AUTOSAR XML (schema 4-2-2)
package /STELLANTIS/EPT/ASWCs
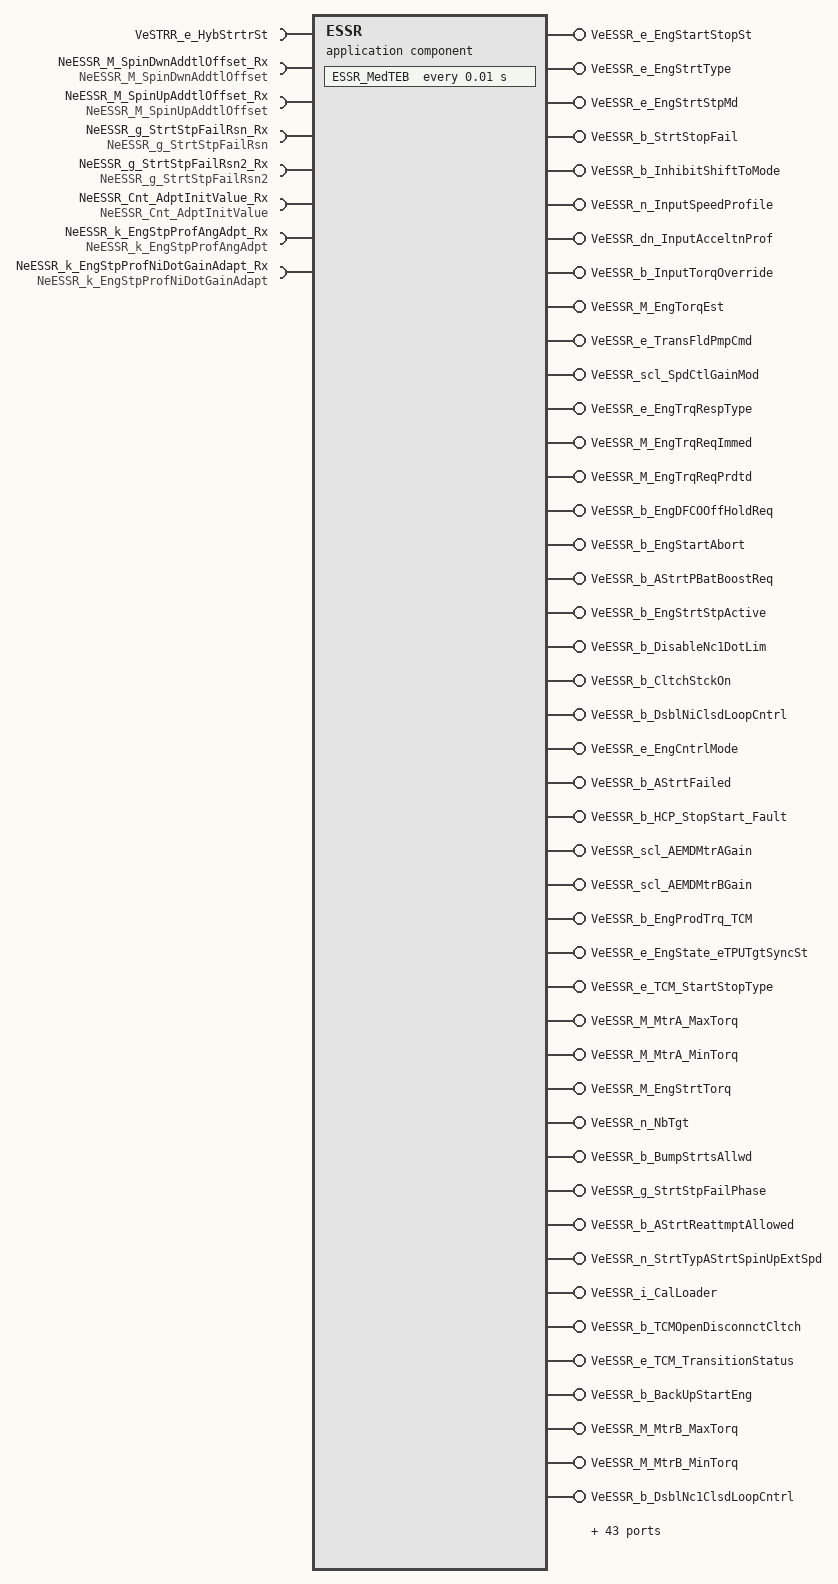
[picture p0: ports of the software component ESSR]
  application sw component type ESSR
    require port VeSTRR_e_HybStrtrSt: variation-point={short-label=vpVeSTRR_e_HybStrtrSt, sw-syscond=1}, nonqueued-receiver-com-spec{data-element=Value, init-value=CeSTRR_e_KeyOffSt}, required-interface=VeSTRR_e_HybStrtrSt
    80 x provide port:
      VeESSR_e_EngStartStopSt: variation-point={short-label=vpVeESSR_e_EngStartStopSt, sw-syscond=1}, nonqueued-sender-com-spec{data-element=Value, init-value=CeESSR_e_EngOff}, provided-interface=VeESSR_e_EngStartStopSt
      VeESSR_e_EngStrtType: variation-point={short-label=vpVeESSR_e_EngStrtType, sw-syscond=1}, nonqueued-sender-com-spec{data-element=Value, init-value=CeESSR_e_NoStrt}, provided-interface=VeESSR_e_EngStrtType
      VeESSR_e_EngStrtStpMd: variation-point={short-label=vpVeESSR_e_EngStrtStpMd, sw-syscond=1}, nonqueued-sender-com-spec{data-element=Value, init-value=CeESSR_e_Stop}, provided-interface=VeESSR_e_EngStrtStpMd
      VeESSR_b_StrtStopFail: variation-point={short-label=vpVeESSR_b_StrtStopFail, sw-syscond=1}, nonqueued-sender-com-spec{data-element=Value, init-value=0}, provided-interface=VeESSR_b_StrtStopFail
      VeESSR_b_InhibitShiftToMode: variation-point={short-label=vpVeESSR_b_InhibitShiftToMode, sw-syscond=1}, nonqueued-sender-com-spec{data-element=Value, init-value=0}, provided-interface=VeESSR_b_InhibitShiftToMode
      VeESSR_n_InputSpeedProfile: variation-point={short-label=vpVeESSR_n_InputSpeedProfile, sw-syscond=1}, nonqueued-sender-com-spec{data-element=Value, init-value=0}, provided-interface=VeESSR_n_InputSpeedProfile
      VeESSR_dn_InputAcceltnProf: variation-point={short-label=vpVeESSR_dn_InputAcceltnProf, sw-syscond=1}, nonqueued-sender-com-spec{data-element=Value, init-value=0}, provided-interface=VeESSR_dn_InputAcceltnProf
      VeESSR_b_InputTorqOverride: variation-point={short-label=vpVeESSR_b_InputTorqOverride, sw-syscond=1}, nonqueued-sender-com-spec{data-element=Value, init-value=0}, provided-interface=VeESSR_b_InputTorqOverride
      VeESSR_M_EngTorqEst: variation-point={short-label=vpVeESSR_M_EngTorqEst, sw-syscond=1}, nonqueued-sender-com-spec{data-element=Value, init-value=0}, provided-interface=VeESSR_M_EngTorqEst
      VeESSR_e_TransFldPmpCmd: variation-point={short-label=vpVeESSR_e_TransFldPmpCmd, sw-syscond=1}, nonqueued-sender-com-spec{data-element=Value, init-value=CeESSR_e_Normal}, provided-interface=VeESSR_e_TransFldPmpCmd
      VeESSR_scl_SpdCtlGainMod: variation-point={short-label=vpVeESSR_scl_SpdCtlGainMod, sw-syscond=1}, nonqueued-sender-com-spec{data-element=Value, init-value=0}, provided-interface=VeESSR_scl_SpdCtlGainMod
      VeESSR_e_EngTrqRespType: variation-point={short-label=vpVeESSR_e_EngTrqRespType, sw-syscond=1}, nonqueued-sender-com-spec{data-element=Value, init-value=CePTAR_e_Inactive}, provided-interface=VeESSR_e_EngTrqRespType
      VeESSR_M_EngTrqReqImmed: variation-point={short-label=vpVeESSR_M_EngTrqReqImmed, sw-syscond=1}, nonqueued-sender-com-spec{data-element=Value, init-value=0}, provided-interface=VeESSR_M_EngTrqReqImmed
      VeESSR_M_EngTrqReqPrdtd: variation-point={short-label=vpVeESSR_M_EngTrqReqPrdtd, sw-syscond=1}, nonqueued-sender-com-spec{data-element=Value, init-value=0}, provided-interface=VeESSR_M_EngTrqReqPrdtd
      VeESSR_b_EngDFCOOffHoldReq: variation-point={short-label=vpVeESSR_b_EngDFCOOffHoldReq, sw-syscond=1}, nonqueued-sender-com-spec{data-element=Value, init-value=0}, provided-interface=VeESSR_b_EngDFCOOffHoldReq
      VeESSR_b_EngStartAbort: variation-point={short-label=vpVeESSR_b_EngStartAbort, sw-syscond=1}, nonqueued-sender-com-spec{data-element=Value, init-value=0}, provided-interface=VeESSR_b_EngStartAbort
      VeESSR_b_AStrtPBatBoostReq: variation-point={short-label=vpVeESSR_b_AStrtPBatBoostReq, sw-syscond=1}, nonqueued-sender-com-spec{data-element=Value, init-value=0}, provided-interface=VeESSR_b_AStrtPBatBoostReq
      VeESSR_b_EngStrtStpActive: variation-point={short-label=vpVeESSR_b_EngStrtStpActive, sw-syscond=1}, nonqueued-sender-com-spec{data-element=Value, init-value=0}, provided-interface=VeESSR_b_EngStrtStpActive
      VeESSR_b_DisableNc1DotLim: variation-point={short-label=vpVeESSR_b_DisableNc1DotLim, sw-syscond=1}, nonqueued-sender-com-spec{data-element=Value, init-value=0}, provided-interface=VeESSR_b_DisableNc1DotLim
      VeESSR_b_CltchStckOn: variation-point={short-label=vpVeESSR_b_CltchStckOn, sw-syscond=1}, nonqueued-sender-com-spec{data-element=Value, init-value=0}, provided-interface=VeESSR_b_CltchStckOn
      VeESSR_b_DsblNiClsdLoopCntrl: variation-point={short-label=vpVeESSR_b_DsblNiClsdLoopCntrl, sw-syscond=1}, nonqueued-sender-com-spec{data-element=Value, init-value=0}, provided-interface=VeESSR_b_DsblNiClsdLoopCntrl
      VeESSR_e_EngCntrlMode: variation-point={short-label=vpVeESSR_e_EngCntrlMode, sw-syscond=1}, nonqueued-sender-com-spec{data-element=Value, init-value=CeTRAR_e_TorqueMode}, provided-interface=VeESSR_e_EngCntrlMode
      VeESSR_b_AStrtFailed: variation-point={short-label=vpVeESSR_b_AStrtFailed, sw-syscond=1}, nonqueued-sender-com-spec{data-element=Value, init-value=0}, provided-interface=VeESSR_b_AStrtFailed
      VeESSR_b_HCP_StopStart_Fault: variation-point={short-label=vpVeESSR_b_HCP_StopStart_Fault, sw-syscond=1}, nonqueued-sender-com-spec{data-element=Value, init-value=0}, provided-interface=VeESSR_b_HCP_StopStart_Fault
      VeESSR_scl_AEMDMtrAGain: variation-point={short-label=vpVeESSR_scl_AEMDMtrAGain, sw-syscond=1}, nonqueued-sender-com-spec{data-element=Value, init-value=0}, provided-interface=VeESSR_scl_AEMDMtrAGain
      VeESSR_scl_AEMDMtrBGain: variation-point={short-label=vpVeESSR_scl_AEMDMtrBGain, sw-syscond=1}, nonqueued-sender-com-spec{data-element=Value, init-value=0}, provided-interface=VeESSR_scl_AEMDMtrBGain
      VeESSR_b_EngProdTrq_TCM: variation-point={short-label=vpVeESSR_b_EngProdTrq_TCM, sw-syscond=1}, nonqueued-sender-com-spec{data-element=Value, init-value=0}, provided-interface=VeESSR_b_EngProdTrq_TCM
      VeESSR_e_EngState_eTPUTgtSyncSt: variation-point={short-label=vpVeESSR_e_EngState_eTPUTgtSyncSt, sw-syscond=1}, nonqueued-sender-com-spec{data-element=Value, init-value=CeESSR_e_Stopped}, provided-interface=VeESSR_e_EngState_eTPUTgtSyncSt
      VeESSR_e_TCM_StartStopType: variation-point={short-label=vpVeESSR_e_TCM_StartStopType, sw-syscond=1}, nonqueued-sender-com-spec{data-element=Value, init-value=CeESSR_e_NoAction}, provided-interface=VeESSR_e_TCM_StartStopType
      VeESSR_M_MtrA_MaxTorq: variation-point={short-label=vpVeESSR_M_MtrA_MaxTorq, sw-syscond=1}, nonqueued-sender-com-spec{data-element=Value, init-value=0}, provided-interface=VeESSR_M_MtrA_MaxTorq
      VeESSR_M_MtrA_MinTorq: variation-point={short-label=vpVeESSR_M_MtrA_MinTorq, sw-syscond=1}, nonqueued-sender-com-spec{data-element=Value, init-value=0}, provided-interface=VeESSR_M_MtrA_MinTorq
      VeESSR_M_EngStrtTorq: variation-point={short-label=vpVeESSR_M_EngStrtTorq, sw-syscond=1}, nonqueued-sender-com-spec{data-element=Value, init-value=0}, provided-interface=VeESSR_M_EngStrtTorq
      VeESSR_n_NbTgt: variation-point={short-label=vpVeESSR_n_NbTgt, sw-syscond=1}, nonqueued-sender-com-spec{data-element=Value, init-value=0}, provided-interface=VeESSR_n_NbTgt
      VeESSR_b_BumpStrtsAllwd: variation-point={short-label=vpVeESSR_b_BumpStrtsAllwd, sw-syscond=1}, nonqueued-sender-com-spec{data-element=Value, init-value=0}, provided-interface=VeESSR_b_BumpStrtsAllwd
      VeESSR_g_StrtStpFailPhase: variation-point={short-label=vpVeESSR_g_StrtStpFailPhase, sw-syscond=1}, nonqueued-sender-com-spec{data-element=Value, init-value=0}, provided-interface=VeESSR_g_StrtStpFailPhase
      VeESSR_b_AStrtReattmptAllowed: variation-point={short-label=vpVeESSR_b_AStrtReattmptAllowed, sw-syscond=1}, nonqueued-sender-com-spec{data-element=Value, init-value=0}, provided-interface=VeESSR_b_AStrtReattmptAllowed
      VeESSR_n_StrtTypAStrtSpinUpExtSpd: variation-point={short-label=vpVeESSR_n_StrtTypAStrtSpinUpExtSpd, sw-syscond=1}, nonqueued-sender-com-spec{data-element=Value, init-value=0}, provided-interface=VeESSR_n_StrtTypAStrtSpinUpExtSpd
      VeESSR_i_CalLoader: variation-point={short-label=vpVeESSR_i_CalLoader, sw-syscond=1}, nonqueued-sender-com-spec{data-element=Value, init-value=0}, provided-interface=VeESSR_i_CalLoader
      VeESSR_b_TCMOpenDisconnctCltch: variation-point={short-label=vpVeESSR_b_TCMOpenDisconnctCltch, sw-syscond=1}, nonqueued-sender-com-spec{data-element=Value, init-value=0}, provided-interface=VeESSR_b_TCMOpenDisconnctCltch
      VeESSR_e_TCM_TransitionStatus: variation-point={short-label=vpVeESSR_e_TCM_TransitionStatus, sw-syscond=1}, nonqueued-sender-com-spec{data-element=Value, init-value=CeESSR_e_Trans_Stat_Off}, provided-interface=VeESSR_e_TCM_TransitionStatus
      VeESSR_b_BackUpStartEng: variation-point={short-label=vpVeESSR_b_BackUpStartEng, sw-syscond=1}, nonqueued-sender-com-spec{data-element=Value, init-value=0}, provided-interface=VeESSR_b_BackUpStartEng
      VeESSR_M_MtrB_MaxTorq: variation-point={short-label=vpVeESSR_M_MtrB_MaxTorq, sw-syscond=1}, nonqueued-sender-com-spec{data-element=Value, init-value=0}, provided-interface=VeESSR_M_MtrB_MaxTorq
      VeESSR_M_MtrB_MinTorq: variation-point={short-label=vpVeESSR_M_MtrB_MinTorq, sw-syscond=1}, nonqueued-sender-com-spec{data-element=Value, init-value=0}, provided-interface=VeESSR_M_MtrB_MinTorq
      VeESSR_b_DsblNc1ClsdLoopCntrl: variation-point={short-label=vpVeESSR_b_DsblNc1ClsdLoopCntrl, sw-syscond=1}, nonqueued-sender-com-spec{data-element=Value, init-value=0}, provided-interface=VeESSR_b_DsblNc1ClsdLoopCntrl
      VeESSR_M_Clch5_TorqCmd: variation-point={short-label=vpVeESSR_M_Clch5_TorqCmd, sw-syscond=1}, nonqueued-sender-com-spec{data-element=Value, init-value=0}, provided-interface=VeESSR_M_Clch5_TorqCmd
      VeESSR_M_MtrC_MaxTorq: variation-point={short-label=vpVeESSR_M_MtrC_MaxTorq, sw-syscond=1}, nonqueued-sender-com-spec{data-element=Value, init-value=0}, provided-interface=VeESSR_M_MtrC_MaxTorq
      VeESSR_M_MtrC_MinTorq: variation-point={short-label=vpVeESSR_M_MtrC_MinTorq, sw-syscond=1}, nonqueued-sender-com-spec{data-element=Value, init-value=0}, provided-interface=VeESSR_M_MtrC_MinTorq
      VeESSR_b_NbTgtReq: variation-point={short-label=vpVeESSR_b_NbTgtReq, sw-syscond=1}, nonqueued-sender-com-spec{data-element=Value, init-value=0}, provided-interface=VeESSR_b_NbTgtReq
      VeESSR_b_EngStallReattmpAllwd: variation-point={short-label=vpVeESSR_b_EngStallReattmpAllwd, sw-syscond=1}, nonqueued-sender-com-spec{data-element=Value, init-value=0}, provided-interface=VeESSR_b_EngStallReattmpAllwd
      VeESSR_M_MtrAPulseCancelTrq: variation-point={short-label=vpVeESSR_M_MtrAPulseCancelTrq, sw-syscond=1}, nonqueued-sender-com-spec{data-element=Value, init-value=0}, provided-interface=VeESSR_M_MtrAPulseCancelTrq
      VeESSR_M_MtrBPulseCancelTrq: variation-point={short-label=vpVeESSR_M_MtrBPulseCancelTrq, sw-syscond=1}, nonqueued-sender-com-spec{data-element=Value, init-value=0}, provided-interface=VeESSR_M_MtrBPulseCancelTrq
      VeESSR_b_IUMPR_P1C64Fail: variation-point={short-label=vpVeESSR_b_IUMPR_P1C64Fail, sw-syscond=1}, nonqueued-sender-com-spec{data-element=Value, init-value=0}, provided-interface=VeESSR_b_IUMPR_P1C64Fail
      VeESSR_b_IUMPR_P1C65Fail: variation-point={short-label=vpVeESSR_b_IUMPR_P1C65Fail, sw-syscond=1}, nonqueued-sender-com-spec{data-element=Value, init-value=0}, provided-interface=VeESSR_b_IUMPR_P1C65Fail
      VeESSR_b_IUMPR_P1C68Fail: variation-point={short-label=vpVeESSR_b_IUMPR_P1C68Fail, sw-syscond=1}, nonqueued-sender-com-spec{data-element=Value, init-value=0}, provided-interface=VeESSR_b_IUMPR_P1C68Fail
      VeESSR_e_HybEngSysActv: variation-point={short-label=vpVeESSR_e_HybEngSysActv, sw-syscond=1}, nonqueued-sender-com-spec{data-element=Value, init-value=CeESSR_e_HybEngDisabled}, provided-interface=VeESSR_e_HybEngSysActv
      VeESSR_b_BSGStrtFailed: variation-point={short-label=vpVeESSR_b_BSGStrtFailed, sw-syscond=1}, nonqueued-sender-com-spec{data-element=Value, init-value=0}, provided-interface=VeESSR_b_BSGStrtFailed
      VeESSR_b_BkupStrtsAllwd: variation-point={short-label=vpVeESSR_b_BkupStrtsAllwd, sw-syscond=1}, nonqueued-sender-com-spec{data-element=Value, init-value=0}, provided-interface=VeESSR_b_BkupStrtsAllwd
      VeESSR_Cnt_CSSpinupAttmptCntr: variation-point={short-label=vpVeESSR_Cnt_CSSpinupAttmptCntr, sw-syscond=1}, nonqueued-sender-com-spec{data-element=Value, init-value=0}, provided-interface=VeESSR_Cnt_CSSpinupAttmptCntr
      VeESSR_Cnt_EMSpinupAttmptCntr: variation-point={short-label=vpVeESSR_Cnt_EMSpinupAttmptCntr, sw-syscond=1}, nonqueued-sender-com-spec{data-element=Value, init-value=0}, provided-interface=VeESSR_Cnt_EMSpinupAttmptCntr
      VeESSR_e_EngStrtProfType: variation-point={short-label=vpVeESSR_e_EngStrtProfType, sw-syscond=1}, nonqueued-sender-com-spec{data-element=Value, init-value=CeESSR_e_NoStart}, provided-interface=VeESSR_e_EngStrtProfType
      VeESSR_n_OptInputSpd: variation-point={short-label=vpVeESSR_n_OptInputSpd, sw-syscond=1}, nonqueued-sender-com-spec{data-element=Value, init-value=0}, provided-interface=VeESSR_n_OptInputSpd
      VeESSR_n_TgtIdleSpd: variation-point={short-label=vpVeESSR_n_TgtIdleSpd, sw-syscond=1}, nonqueued-sender-com-spec{data-element=Value, init-value=0}, provided-interface=VeESSR_n_TgtIdleSpd
      VeESSR_b_OptimdEngOnOffCmd: variation-point={short-label=vpVeESSR_b_OptimdEngOnOffCmd, sw-syscond=1}, nonqueued-sender-com-spec{data-element=Value, init-value=0}, provided-interface=VeESSR_b_OptimdEngOnOffCmd
      VeESSR_b_HCPFuelDisable: variation-point={short-label=vpVeESSR_b_HCPFuelDisable, sw-syscond=1}, nonqueued-sender-com-spec{data-element=Value, init-value=0}, provided-interface=VeESSR_b_HCPFuelDisable
      VeESSR_b_Hyb_ProducingTorque: variation-point={short-label=vpVeESSR_b_Hyb_ProducingTorque, sw-syscond=1}, nonqueued-sender-com-spec{data-element=Value, init-value=0}, provided-interface=VeESSR_b_Hyb_ProducingTorque
      VeESSR_e_OptimdEngStrtStpType: variation-point={short-label=vpVeESSR_e_OptimdEngStrtStpType, sw-syscond=1}, nonqueued-sender-com-spec{data-element=Value, init-value=CeESSR_e_NoStrt}, provided-interface=VeESSR_e_OptimdEngStrtStpType
      VeESSR_e_OptimdStrtReqdActr: variation-point={short-label=vpVeESSR_e_OptimdStrtReqdActr, sw-syscond=1}, nonqueued-sender-com-spec{data-element=Value, init-value=CeESSR_e_NoActTyp}, provided-interface=VeESSR_e_OptimdStrtReqdActr
      VeESSR_b_EngOffAllwdECM: variation-point={short-label=vpVeESSR_b_EngOffAllwdECM, sw-syscond=1}, nonqueued-sender-com-spec{data-element=Value, init-value=0}, provided-interface=VeESSR_b_EngOffAllwdECM
      VeESSR_r_MaxSparkAuthority: variation-point={short-label=vpVeESSR_r_MaxSparkAuthority, sw-syscond=1}, nonqueued-sender-com-spec{data-element=Value, init-value=0}, provided-interface=VeESSR_r_MaxSparkAuthority
      VeESSR_M_EngineLosses: variation-point={short-label=vpVeESSR_M_EngineLosses, sw-syscond=1}, nonqueued-sender-com-spec{data-element=Value, init-value=0}, provided-interface=VeESSR_M_EngineLosses
      VeESSR_b_P1C64_Failed: variation-point={short-label=vpVeESSR_b_P1C64_Failed, sw-syscond=1}, nonqueued-sender-com-spec{data-element=Value, init-value=0}, provided-interface=VeESSR_b_P1C64_Failed
      VeESSR_b_P1C65_Failed: variation-point={short-label=vpVeESSR_b_P1C65_Failed, sw-syscond=1}, nonqueued-sender-com-spec{data-element=Value, init-value=0}, provided-interface=VeESSR_b_P1C65_Failed
      VeESSR_b_P1C68_Failed: variation-point={short-label=vpVeESSR_b_P1C68_Failed, sw-syscond=1}, nonqueued-sender-com-spec{data-element=Value, init-value=0}, provided-interface=VeESSR_b_P1C68_Failed
      VeESSR_b_P1C64_Passed: variation-point={short-label=vpVeESSR_b_P1C64_Passed, sw-syscond=1}, nonqueued-sender-com-spec{data-element=Value, init-value=0}, provided-interface=VeESSR_b_P1C64_Passed
      VeESSR_b_P1C65_Passed: variation-point={short-label=vpVeESSR_b_P1C65_Passed, sw-syscond=1}, nonqueued-sender-com-spec{data-element=Value, init-value=0}, provided-interface=VeESSR_b_P1C65_Passed
      VeESSR_b_P1C68_Passed: variation-point={short-label=vpVeESSR_b_P1C68_Passed, sw-syscond=1}, nonqueued-sender-com-spec{data-element=Value, init-value=0}, provided-interface=VeESSR_b_P1C68_Passed
      VeESSR_n_NiPred: variation-point={short-label=vpVeESSR_n_NiPred, sw-syscond=1}, nonqueued-sender-com-spec{data-element=Value, init-value=0}, provided-interface=VeESSR_n_NiPred
      VeESSR_b_DisableMtrA: variation-point={short-label=vpVeESSR_b_DisableMtrA, sw-syscond=1}, nonqueued-sender-com-spec{data-element=Value, init-value=0}, provided-interface=VeESSR_b_DisableMtrA
      VeESSR_M_BCTiMargin: variation-point={short-label=vpVeESSR_M_BCTiMargin, sw-syscond=1}, nonqueued-sender-com-spec{data-element=Value, init-value=0}, provided-interface=VeESSR_M_BCTiMargin
      VeESSR_g_StrtStpFailRsn: variation-point={short-label=vpVeESSR_g_StrtStpFailRsn, sw-syscond=1}, nonqueued-sender-com-spec{data-element=Value, init-value=0}, provided-interface=VeESSR_g_StrtStpFailRsn
    7 x require port:
      NeESSR_M_SpinDwnAddtlOffset_Rx: nv-require-com-spec{init-value=0, variable=NeESSR_M_SpinDwnAddtlOffset}, required-interface=NeESSR_M_SpinDwnAddtlOffset
      NeESSR_M_SpinUpAddtlOffset_Rx: nv-require-com-spec{init-value=0, variable=NeESSR_M_SpinUpAddtlOffset}, required-interface=NeESSR_M_SpinUpAddtlOffset
      NeESSR_g_StrtStpFailRsn_Rx: nv-require-com-spec{init-value=0, variable=NeESSR_g_StrtStpFailRsn}, required-interface=NeESSR_g_StrtStpFailRsn
      NeESSR_g_StrtStpFailRsn2_Rx: nv-require-com-spec{init-value=0, variable=NeESSR_g_StrtStpFailRsn2}, required-interface=NeESSR_g_StrtStpFailRsn2
      NeESSR_Cnt_AdptInitValue_Rx: nv-require-com-spec{init-value=0, variable=NeESSR_Cnt_AdptInitValue}, required-interface=NeESSR_Cnt_AdptInitValue
      NeESSR_k_EngStpProfAngAdpt_Rx: nv-require-com-spec{init-value=0, variable=NeESSR_k_EngStpProfAngAdpt}, required-interface=NeESSR_k_EngStpProfAngAdpt
      NeESSR_k_EngStpProfNiDotGainAdapt_Rx: nv-require-com-spec{init-value=0, variable=NeESSR_k_EngStpProfNiDotGainAdapt}, required-interface=NeESSR_k_EngStpProfNiDotGainAdapt
    7 x provide port:
      NeESSR_M_SpinDwnAddtlOffset: nv-provide-com-spec{ram-block-init-value=0, variable=NeESSR_M_SpinDwnAddtlOffset}, provided-interface=NeESSR_M_SpinDwnAddtlOffset
      NeESSR_M_SpinUpAddtlOffset: nv-provide-com-spec{ram-block-init-value=0, variable=NeESSR_M_SpinUpAddtlOffset}, provided-interface=NeESSR_M_SpinUpAddtlOffset
      NeESSR_g_StrtStpFailRsn: nv-provide-com-spec{ram-block-init-value=0, variable=NeESSR_g_StrtStpFailRsn}, provided-interface=NeESSR_g_StrtStpFailRsn
      NeESSR_g_StrtStpFailRsn2: nv-provide-com-spec{ram-block-init-value=0, variable=NeESSR_g_StrtStpFailRsn2}, provided-interface=NeESSR_g_StrtStpFailRsn2
      NeESSR_Cnt_AdptInitValue: nv-provide-com-spec{ram-block-init-value=0, variable=NeESSR_Cnt_AdptInitValue}, provided-interface=NeESSR_Cnt_AdptInitValue
      NeESSR_k_EngStpProfAngAdpt: nv-provide-com-spec{ram-block-init-value=0, variable=NeESSR_k_EngStpProfAngAdpt}, provided-interface=NeESSR_k_EngStpProfAngAdpt
      NeESSR_k_EngStpProfNiDotGainAdapt: nv-provide-com-spec{ram-block-init-value=0, variable=NeESSR_k_EngStpProfNiDotGainAdapt}, provided-interface=NeESSR_k_EngStpProfNiDotGainAdapt
    behavior IB_ESSR: data-type-mapping=msADTtoIDTMapping, handle-termination-and-restart=NO-SUPPORT, included-data-type-set=data-type=[TeESSR_e_IdleCtrlrSelect, TeESSR_e_STMTrigger, TeESSR_e_StrtStpFailDTC]
      timing event Event_MedTEB: start-on-event=ESSR_MedTEB, period=0.01
      init event Event_ESSR_ac_Init: start-on-event=ESSR_ac_Init
      init event Event_PwrOn: start-on-event=ESSR_PwrOn
      init event Event_PwrOff: start-on-event=ESSR_PwrOff
      4 x runnable:
        ESSR_ac_Init
          data-send-points:
            13 x access:
              OUT_VeESSR_e_EngStartStopSt_Value: accessed-variable=VeESSR_e_EngStartStopSt.Value, variation-point={short-label=vpOUT_VeESSR_e_EngStartStopSt_Value, sw-syscond=1}
              OUT_VeESSR_e_EngStrtType_Value: accessed-variable=VeESSR_e_EngStrtType.Value, variation-point={short-label=vpOUT_VeESSR_e_EngStrtType_Value, sw-syscond=1}
              OUT_VeESSR_e_EngStrtStpMd_Value: accessed-variable=VeESSR_e_EngStrtStpMd.Value, variation-point={short-label=vpOUT_VeESSR_e_EngStrtStpMd_Value, sw-syscond=1}
              OUT_VeESSR_e_TransFldPmpCmd_Value: accessed-variable=VeESSR_e_TransFldPmpCmd.Value, variation-point={short-label=vpOUT_VeESSR_e_TransFldPmpCmd_Value, sw-syscond=1}
              OUT_VeESSR_e_EngTrqRespType_Value: accessed-variable=VeESSR_e_EngTrqRespType.Value, variation-point={short-label=vpOUT_VeESSR_e_EngTrqRespType_Value, sw-syscond=1}
              OUT_VeESSR_e_EngCntrlMode_Value: accessed-variable=VeESSR_e_EngCntrlMode.Value, variation-point={short-label=vpOUT_VeESSR_e_EngCntrlMode_Value, sw-syscond=1}
              OUT_VeESSR_e_EngState_eTPUTgtSyncSt_Value: accessed-variable=VeESSR_e_EngState_eTPUTgtSyncSt.Value, variation-point={short-label=vpOUT_VeESSR_e_EngState_eTPUTgtSyncSt_Value, sw-syscond=1}
              OUT_VeESSR_e_TCM_StartStopType_Value: accessed-variable=VeESSR_e_TCM_StartStopType.Value, variation-point={short-label=vpOUT_VeESSR_e_TCM_StartStopType_Value, sw-syscond=1}
              OUT_VeESSR_e_TCM_TransitionStatus_Value: accessed-variable=VeESSR_e_TCM_TransitionStatus.Value, variation-point={short-label=vpOUT_VeESSR_e_TCM_TransitionStatus_Value, sw-syscond=1}
              OUT_VeESSR_e_HybEngSysActv_Value: accessed-variable=VeESSR_e_HybEngSysActv.Value, variation-point={short-label=vpOUT_VeESSR_e_HybEngSysActv_Value, sw-syscond=1}
              OUT_VeESSR_e_EngStrtProfType_Value: accessed-variable=VeESSR_e_EngStrtProfType.Value, variation-point={short-label=vpOUT_VeESSR_e_EngStrtProfType_Value, sw-syscond=1}
              OUT_VeESSR_e_OptimdEngStrtStpType_Value: accessed-variable=VeESSR_e_OptimdEngStrtStpType.Value, variation-point={short-label=vpOUT_VeESSR_e_OptimdEngStrtStpType_Value, sw-syscond=1}
              OUT_VeESSR_e_OptimdStrtReqdActr_Value: accessed-variable=VeESSR_e_OptimdStrtReqdActr.Value, variation-point={short-label=vpOUT_VeESSR_e_OptimdStrtReqdActr_Value, sw-syscond=1}
        ESSR_PwrOn
          data-receive-point-by-arguments:
            7 x access:
              IN_NeESSR_Cnt_AdptInitValue_Rx_NeESSR_Cnt_AdptInitValue: accessed-variable=NeESSR_Cnt_AdptInitValue_Rx.NeESSR_Cnt_AdptInitValue
              IN_NeESSR_M_SpinDwnAddtlOffset_Rx_NeESSR_M_SpinDwnAddtlOffset: accessed-variable=NeESSR_M_SpinDwnAddtlOffset_Rx.NeESSR_M_SpinDwnAddtlOffset
              IN_NeESSR_M_SpinUpAddtlOffset_Rx_NeESSR_M_SpinUpAddtlOffset: accessed-variable=NeESSR_M_SpinUpAddtlOffset_Rx.NeESSR_M_SpinUpAddtlOffset
              IN_NeESSR_g_StrtStpFailRsn2_Rx_NeESSR_g_StrtStpFailRsn2: accessed-variable=NeESSR_g_StrtStpFailRsn2_Rx.NeESSR_g_StrtStpFailRsn2
              IN_NeESSR_g_StrtStpFailRsn_Rx_NeESSR_g_StrtStpFailRsn: accessed-variable=NeESSR_g_StrtStpFailRsn_Rx.NeESSR_g_StrtStpFailRsn
              IN_NeESSR_k_EngStpProfAngAdpt_Rx_NeESSR_k_EngStpProfAngAdpt: accessed-variable=NeESSR_k_EngStpProfAngAdpt_Rx.NeESSR_k_EngStpProfAngAdpt
              IN_NeESSR_k_EngStpProfNiDotGainAdapt_Rx_NeESSR_k_EngStpProfNiDotGainAdapt: accessed-variable=NeESSR_k_EngStpProfNiDotGainAdapt_Rx.NeESSR_k_EngStpProfNiDotGainAdapt
          data-send-points:
            80 x access:
              OUT_VeESSR_e_EngStartStopSt_Value: accessed-variable=VeESSR_e_EngStartStopSt.Value, variation-point={short-label=vpOUT_VeESSR_e_EngStartStopSt_Value, sw-syscond=1}
              OUT_VeESSR_e_TransFldPmpCmd_Value: accessed-variable=VeESSR_e_TransFldPmpCmd.Value, variation-point={short-label=vpOUT_VeESSR_e_TransFldPmpCmd_Value, sw-syscond=1}
              OUT_VeESSR_scl_SpdCtlGainMod_Value: accessed-variable=VeESSR_scl_SpdCtlGainMod.Value, variation-point={short-label=vpOUT_VeESSR_scl_SpdCtlGainMod_Value, sw-syscond=1}
              OUT_VeESSR_e_EngTrqRespType_Value: accessed-variable=VeESSR_e_EngTrqRespType.Value, variation-point={short-label=vpOUT_VeESSR_e_EngTrqRespType_Value, sw-syscond=1}
              OUT_VeESSR_M_EngTrqReqImmed_Value: accessed-variable=VeESSR_M_EngTrqReqImmed.Value, variation-point={short-label=vpOUT_VeESSR_M_EngTrqReqImmed_Value, sw-syscond=1}
              OUT_VeESSR_M_EngTrqReqPrdtd_Value: accessed-variable=VeESSR_M_EngTrqReqPrdtd.Value, variation-point={short-label=vpOUT_VeESSR_M_EngTrqReqPrdtd_Value, sw-syscond=1}
              OUT_VeESSR_b_EngDFCOOffHoldReq_Value: accessed-variable=VeESSR_b_EngDFCOOffHoldReq.Value, variation-point={short-label=vpOUT_VeESSR_b_EngDFCOOffHoldReq_Value, sw-syscond=1}
              OUT_VeESSR_b_EngStartAbort_Value: accessed-variable=VeESSR_b_EngStartAbort.Value, variation-point={short-label=vpOUT_VeESSR_b_EngStartAbort_Value, sw-syscond=1}
              OUT_VeESSR_b_AStrtPBatBoostReq_Value: accessed-variable=VeESSR_b_AStrtPBatBoostReq.Value, variation-point={short-label=vpOUT_VeESSR_b_AStrtPBatBoostReq_Value, sw-syscond=1}
              OUT_VeESSR_b_EngStrtStpActive_Value: accessed-variable=VeESSR_b_EngStrtStpActive.Value, variation-point={short-label=vpOUT_VeESSR_b_EngStrtStpActive_Value, sw-syscond=1}
              OUT_VeESSR_b_DisableNc1DotLim_Value: accessed-variable=VeESSR_b_DisableNc1DotLim.Value, variation-point={short-label=vpOUT_VeESSR_b_DisableNc1DotLim_Value, sw-syscond=1}
              OUT_VeESSR_e_EngStrtType_Value: accessed-variable=VeESSR_e_EngStrtType.Value, variation-point={short-label=vpOUT_VeESSR_e_EngStrtType_Value, sw-syscond=1}
              OUT_VeESSR_b_CltchStckOn_Value: accessed-variable=VeESSR_b_CltchStckOn.Value, variation-point={short-label=vpOUT_VeESSR_b_CltchStckOn_Value, sw-syscond=1}
              OUT_VeESSR_b_DsblNiClsdLoopCntrl_Value: accessed-variable=VeESSR_b_DsblNiClsdLoopCntrl.Value, variation-point={short-label=vpOUT_VeESSR_b_DsblNiClsdLoopCntrl_Value, sw-syscond=1}
              OUT_VeESSR_e_EngCntrlMode_Value: accessed-variable=VeESSR_e_EngCntrlMode.Value, variation-point={short-label=vpOUT_VeESSR_e_EngCntrlMode_Value, sw-syscond=1}
              OUT_VeESSR_b_AStrtFailed_Value: accessed-variable=VeESSR_b_AStrtFailed.Value, variation-point={short-label=vpOUT_VeESSR_b_AStrtFailed_Value, sw-syscond=1}
              OUT_VeESSR_b_HCP_StopStart_Fault_Value: accessed-variable=VeESSR_b_HCP_StopStart_Fault.Value, variation-point={short-label=vpOUT_VeESSR_b_HCP_StopStart_Fault_Value, sw-syscond=1}
              OUT_VeESSR_scl_AEMDMtrAGain_Value: accessed-variable=VeESSR_scl_AEMDMtrAGain.Value, variation-point={short-label=vpOUT_VeESSR_scl_AEMDMtrAGain_Value, sw-syscond=1}
              OUT_VeESSR_scl_AEMDMtrBGain_Value: accessed-variable=VeESSR_scl_AEMDMtrBGain.Value, variation-point={short-label=vpOUT_VeESSR_scl_AEMDMtrBGain_Value, sw-syscond=1}
              OUT_VeESSR_b_EngProdTrq_TCM_Value: accessed-variable=VeESSR_b_EngProdTrq_TCM.Value, variation-point={short-label=vpOUT_VeESSR_b_EngProdTrq_TCM_Value, sw-syscond=1}
              OUT_VeESSR_e_EngState_eTPUTgtSyncSt_Value: accessed-variable=VeESSR_e_EngState_eTPUTgtSyncSt.Value, variation-point={short-label=vpOUT_VeESSR_e_EngState_eTPUTgtSyncSt_Value, sw-syscond=1}
              OUT_VeESSR_e_TCM_StartStopType_Value: accessed-variable=VeESSR_e_TCM_StartStopType.Value, variation-point={short-label=vpOUT_VeESSR_e_TCM_StartStopType_Value, sw-syscond=1}
              OUT_VeESSR_e_EngStrtStpMd_Value: accessed-variable=VeESSR_e_EngStrtStpMd.Value, variation-point={short-label=vpOUT_VeESSR_e_EngStrtStpMd_Value, sw-syscond=1}
              OUT_VeESSR_M_MtrA_MaxTorq_Value: accessed-variable=VeESSR_M_MtrA_MaxTorq.Value, variation-point={short-label=vpOUT_VeESSR_M_MtrA_MaxTorq_Value, sw-syscond=1}
              OUT_VeESSR_M_MtrA_MinTorq_Value: accessed-variable=VeESSR_M_MtrA_MinTorq.Value, variation-point={short-label=vpOUT_VeESSR_M_MtrA_MinTorq_Value, sw-syscond=1}
              OUT_VeESSR_M_EngStrtTorq_Value: accessed-variable=VeESSR_M_EngStrtTorq.Value, variation-point={short-label=vpOUT_VeESSR_M_EngStrtTorq_Value, sw-syscond=1}
              OUT_VeESSR_n_NbTgt_Value: accessed-variable=VeESSR_n_NbTgt.Value, variation-point={short-label=vpOUT_VeESSR_n_NbTgt_Value, sw-syscond=1}
              OUT_VeESSR_b_BumpStrtsAllwd_Value: accessed-variable=VeESSR_b_BumpStrtsAllwd.Value, variation-point={short-label=vpOUT_VeESSR_b_BumpStrtsAllwd_Value, sw-syscond=1}
              OUT_VeESSR_g_StrtStpFailPhase_Value: accessed-variable=VeESSR_g_StrtStpFailPhase.Value, variation-point={short-label=vpOUT_VeESSR_g_StrtStpFailPhase_Value, sw-syscond=1}
              OUT_VeESSR_b_AStrtReattmptAllowed_Value: accessed-variable=VeESSR_b_AStrtReattmptAllowed.Value, variation-point={short-label=vpOUT_VeESSR_b_AStrtReattmptAllowed_Value, sw-syscond=1}
              OUT_VeESSR_n_StrtTypAStrtSpinUpExtSpd_Value: accessed-variable=VeESSR_n_StrtTypAStrtSpinUpExtSpd.Value, variation-point={short-label=vpOUT_VeESSR_n_StrtTypAStrtSpinUpExtSpd_Value, sw-syscond=1}
              OUT_VeESSR_i_CalLoader_Value: accessed-variable=VeESSR_i_CalLoader.Value, variation-point={short-label=vpOUT_VeESSR_i_CalLoader_Value, sw-syscond=1}
              OUT_VeESSR_b_TCMOpenDisconnctCltch_Value: accessed-variable=VeESSR_b_TCMOpenDisconnctCltch.Value, variation-point={short-label=vpOUT_VeESSR_b_TCMOpenDisconnctCltch_Value, sw-syscond=1}
              OUT_VeESSR_b_StrtStopFail_Value: accessed-variable=VeESSR_b_StrtStopFail.Value, variation-point={short-label=vpOUT_VeESSR_b_StrtStopFail_Value, sw-syscond=1}
              OUT_VeESSR_e_TCM_TransitionStatus_Value: accessed-variable=VeESSR_e_TCM_TransitionStatus.Value, variation-point={short-label=vpOUT_VeESSR_e_TCM_TransitionStatus_Value, sw-syscond=1}
              OUT_VeESSR_b_BackUpStartEng_Value: accessed-variable=VeESSR_b_BackUpStartEng.Value, variation-point={short-label=vpOUT_VeESSR_b_BackUpStartEng_Value, sw-syscond=1}
              OUT_VeESSR_M_MtrB_MaxTorq_Value: accessed-variable=VeESSR_M_MtrB_MaxTorq.Value, variation-point={short-label=vpOUT_VeESSR_M_MtrB_MaxTorq_Value, sw-syscond=1}
              OUT_VeESSR_M_MtrB_MinTorq_Value: accessed-variable=VeESSR_M_MtrB_MinTorq.Value, variation-point={short-label=vpOUT_VeESSR_M_MtrB_MinTorq_Value, sw-syscond=1}
              OUT_VeESSR_b_DsblNc1ClsdLoopCntrl_Value: accessed-variable=VeESSR_b_DsblNc1ClsdLoopCntrl.Value, variation-point={short-label=vpOUT_VeESSR_b_DsblNc1ClsdLoopCntrl_Value, sw-syscond=1}
              OUT_VeESSR_M_Clch5_TorqCmd_Value: accessed-variable=VeESSR_M_Clch5_TorqCmd.Value, variation-point={short-label=vpOUT_VeESSR_M_Clch5_TorqCmd_Value, sw-syscond=1}
              OUT_VeESSR_M_MtrC_MaxTorq_Value: accessed-variable=VeESSR_M_MtrC_MaxTorq.Value, variation-point={short-label=vpOUT_VeESSR_M_MtrC_MaxTorq_Value, sw-syscond=1}
              OUT_VeESSR_M_MtrC_MinTorq_Value: accessed-variable=VeESSR_M_MtrC_MinTorq.Value, variation-point={short-label=vpOUT_VeESSR_M_MtrC_MinTorq_Value, sw-syscond=1}
              OUT_VeESSR_b_NbTgtReq_Value: accessed-variable=VeESSR_b_NbTgtReq.Value, variation-point={short-label=vpOUT_VeESSR_b_NbTgtReq_Value, sw-syscond=1}
              OUT_VeESSR_b_EngStallReattmpAllwd_Value: accessed-variable=VeESSR_b_EngStallReattmpAllwd.Value, variation-point={short-label=vpOUT_VeESSR_b_EngStallReattmpAllwd_Value, sw-syscond=1}
              OUT_VeESSR_b_InhibitShiftToMode_Value: accessed-variable=VeESSR_b_InhibitShiftToMode.Value, variation-point={short-label=vpOUT_VeESSR_b_InhibitShiftToMode_Value, sw-syscond=1}
              OUT_VeESSR_b_BSGStrtFailed_Value: accessed-variable=VeESSR_b_BSGStrtFailed.Value, variation-point={short-label=vpOUT_VeESSR_b_BSGStrtFailed_Value, sw-syscond=1}
              OUT_VeESSR_b_BkupStrtsAllwd_Value: accessed-variable=VeESSR_b_BkupStrtsAllwd.Value, variation-point={short-label=vpOUT_VeESSR_b_BkupStrtsAllwd_Value, sw-syscond=1}
              OUT_VeESSR_Cnt_CSSpinupAttmptCntr_Value: accessed-variable=VeESSR_Cnt_CSSpinupAttmptCntr.Value, variation-point={short-label=vpOUT_VeESSR_Cnt_CSSpinupAttmptCntr_Value, sw-syscond=1}
              OUT_VeESSR_Cnt_EMSpinupAttmptCntr_Value: accessed-variable=VeESSR_Cnt_EMSpinupAttmptCntr.Value, variation-point={short-label=vpOUT_VeESSR_Cnt_EMSpinupAttmptCntr_Value, sw-syscond=1}
              OUT_VeESSR_e_EngStrtProfType_Value: accessed-variable=VeESSR_e_EngStrtProfType.Value, variation-point={short-label=vpOUT_VeESSR_e_EngStrtProfType_Value, sw-syscond=1}
              OUT_VeESSR_n_OptInputSpd_Value: accessed-variable=VeESSR_n_OptInputSpd.Value, variation-point={short-label=vpOUT_VeESSR_n_OptInputSpd_Value, sw-syscond=1}
              OUT_VeESSR_n_TgtIdleSpd_Value: accessed-variable=VeESSR_n_TgtIdleSpd.Value, variation-point={short-label=vpOUT_VeESSR_n_TgtIdleSpd_Value, sw-syscond=1}
              OUT_VeESSR_b_OptimdEngOnOffCmd_Value: accessed-variable=VeESSR_b_OptimdEngOnOffCmd.Value, variation-point={short-label=vpOUT_VeESSR_b_OptimdEngOnOffCmd_Value, sw-syscond=1}
              OUT_VeESSR_b_HCPFuelDisable_Value: accessed-variable=VeESSR_b_HCPFuelDisable.Value, variation-point={short-label=vpOUT_VeESSR_b_HCPFuelDisable_Value, sw-syscond=1}
              OUT_VeESSR_b_Hyb_ProducingTorque_Value: accessed-variable=VeESSR_b_Hyb_ProducingTorque.Value, variation-point={short-label=vpOUT_VeESSR_b_Hyb_ProducingTorque_Value, sw-syscond=1}
              OUT_VeESSR_n_InputSpeedProfile_Value: accessed-variable=VeESSR_n_InputSpeedProfile.Value, variation-point={short-label=vpOUT_VeESSR_n_InputSpeedProfile_Value, sw-syscond=1}
              OUT_VeESSR_e_OptimdEngStrtStpType_Value: accessed-variable=VeESSR_e_OptimdEngStrtStpType.Value, variation-point={short-label=vpOUT_VeESSR_e_OptimdEngStrtStpType_Value, sw-syscond=1}
              OUT_VeESSR_e_OptimdStrtReqdActr_Value: accessed-variable=VeESSR_e_OptimdStrtReqdActr.Value, variation-point={short-label=vpOUT_VeESSR_e_OptimdStrtReqdActr_Value, sw-syscond=1}
              OUT_VeESSR_b_EngOffAllwdECM_Value: accessed-variable=VeESSR_b_EngOffAllwdECM.Value, variation-point={short-label=vpOUT_VeESSR_b_EngOffAllwdECM_Value, sw-syscond=1}
              OUT_VeESSR_M_MtrAPulseCancelTrq_Value: accessed-variable=VeESSR_M_MtrAPulseCancelTrq.Value, variation-point={short-label=vpOUT_VeESSR_M_MtrAPulseCancelTrq_Value, sw-syscond=1}
              OUT_VeESSR_M_MtrBPulseCancelTrq_Value: accessed-variable=VeESSR_M_MtrBPulseCancelTrq.Value, variation-point={short-label=vpOUT_VeESSR_M_MtrBPulseCancelTrq_Value, sw-syscond=1}
              OUT_VeESSR_b_IUMPR_P1C64Fail_Value: accessed-variable=VeESSR_b_IUMPR_P1C64Fail.Value, variation-point={short-label=vpOUT_VeESSR_b_IUMPR_P1C64Fail_Value, sw-syscond=1}
              OUT_VeESSR_b_IUMPR_P1C65Fail_Value: accessed-variable=VeESSR_b_IUMPR_P1C65Fail.Value, variation-point={short-label=vpOUT_VeESSR_b_IUMPR_P1C65Fail_Value, sw-syscond=1}
              OUT_VeESSR_b_IUMPR_P1C68Fail_Value: accessed-variable=VeESSR_b_IUMPR_P1C68Fail.Value, variation-point={short-label=vpOUT_VeESSR_b_IUMPR_P1C68Fail_Value, sw-syscond=1}
              OUT_VeESSR_r_MaxSparkAuthority_Value: accessed-variable=VeESSR_r_MaxSparkAuthority.Value, variation-point={short-label=vpOUT_VeESSR_r_MaxSparkAuthority_Value, sw-syscond=1}
              OUT_VeESSR_dn_InputAcceltnProf_Value: accessed-variable=VeESSR_dn_InputAcceltnProf.Value, variation-point={short-label=vpOUT_VeESSR_dn_InputAcceltnProf_Value, sw-syscond=1}
              OUT_VeESSR_M_EngineLosses_Value: accessed-variable=VeESSR_M_EngineLosses.Value, variation-point={short-label=vpOUT_VeESSR_M_EngineLosses_Value, sw-syscond=1}
              OUT_VeESSR_b_P1C64_Failed_Value: accessed-variable=VeESSR_b_P1C64_Failed.Value, variation-point={short-label=vpOUT_VeESSR_b_P1C64_Failed_Value, sw-syscond=1}
              OUT_VeESSR_b_P1C65_Failed_Value: accessed-variable=VeESSR_b_P1C65_Failed.Value, variation-point={short-label=vpOUT_VeESSR_b_P1C65_Failed_Value, sw-syscond=1}
              OUT_VeESSR_b_P1C68_Failed_Value: accessed-variable=VeESSR_b_P1C68_Failed.Value, variation-point={short-label=vpOUT_VeESSR_b_P1C68_Failed_Value, sw-syscond=1}
              OUT_VeESSR_b_P1C64_Passed_Value: accessed-variable=VeESSR_b_P1C64_Passed.Value, variation-point={short-label=vpOUT_VeESSR_b_P1C64_Passed_Value, sw-syscond=1}
              OUT_VeESSR_b_P1C65_Passed_Value: accessed-variable=VeESSR_b_P1C65_Passed.Value, variation-point={short-label=vpOUT_VeESSR_b_P1C65_Passed_Value, sw-syscond=1}
              OUT_VeESSR_b_P1C68_Passed_Value: accessed-variable=VeESSR_b_P1C68_Passed.Value, variation-point={short-label=vpOUT_VeESSR_b_P1C68_Passed_Value, sw-syscond=1}
              OUT_VeESSR_n_NiPred_Value: accessed-variable=VeESSR_n_NiPred.Value, variation-point={short-label=vpOUT_VeESSR_n_NiPred_Value, sw-syscond=1}
              OUT_VeESSR_b_InputTorqOverride_Value: accessed-variable=VeESSR_b_InputTorqOverride.Value, variation-point={short-label=vpOUT_VeESSR_b_InputTorqOverride_Value, sw-syscond=1}
              OUT_VeESSR_M_EngTorqEst_Value: accessed-variable=VeESSR_M_EngTorqEst.Value, variation-point={short-label=vpOUT_VeESSR_M_EngTorqEst_Value, sw-syscond=1}
              OUT_VeESSR_e_HybEngSysActv_Value: accessed-variable=VeESSR_e_HybEngSysActv.Value, variation-point={short-label=vpOUT_VeESSR_e_HybEngSysActv_Value, sw-syscond=1}
              OUT_VeESSR_b_DisableMtrA_Value: accessed-variable=VeESSR_b_DisableMtrA.Value, variation-point={short-label=vpOUT_VeESSR_b_DisableMtrA_Value, sw-syscond=1}
              OUT_VeESSR_M_BCTiMargin_Value: accessed-variable=VeESSR_M_BCTiMargin.Value, variation-point={short-label=vpOUT_VeESSR_M_BCTiMargin_Value, sw-syscond=1}
              OUT_VeESSR_g_StrtStpFailRsn_Value: accessed-variable=VeESSR_g_StrtStpFailRsn.Value, variation-point={short-label=vpOUT_VeESSR_g_StrtStpFailRsn_Value, sw-syscond=1}
        ESSR_MedTEB
          data-receive-point-by-arguments:
            access IN_VeSTRR_e_HybStrtrSt_Value: accessed-variable=VeSTRR_e_HybStrtrSt.Value, variation-point={short-label=vpIN_VeSTRR_e_HybStrtrSt_Value, sw-syscond=1}
          data-send-points:
            78 x access:
              OUT_VeESSR_b_IUMPR_P1C64Fail_Value: accessed-variable=VeESSR_b_IUMPR_P1C64Fail.Value, variation-point={short-label=vpOUT_VeESSR_b_IUMPR_P1C64Fail_Value, sw-syscond=1}
              OUT_VeESSR_b_IUMPR_P1C65Fail_Value: accessed-variable=VeESSR_b_IUMPR_P1C65Fail.Value, variation-point={short-label=vpOUT_VeESSR_b_IUMPR_P1C65Fail_Value, sw-syscond=1}
              OUT_VeESSR_b_IUMPR_P1C68Fail_Value: accessed-variable=VeESSR_b_IUMPR_P1C68Fail.Value, variation-point={short-label=vpOUT_VeESSR_b_IUMPR_P1C68Fail_Value, sw-syscond=1}
              OUT_VeESSR_b_P1C64_Failed_Value: accessed-variable=VeESSR_b_P1C64_Failed.Value, variation-point={short-label=vpOUT_VeESSR_b_P1C64_Failed_Value, sw-syscond=1}
              OUT_VeESSR_b_P1C65_Failed_Value: accessed-variable=VeESSR_b_P1C65_Failed.Value, variation-point={short-label=vpOUT_VeESSR_b_P1C65_Failed_Value, sw-syscond=1}
              OUT_VeESSR_b_P1C68_Failed_Value: accessed-variable=VeESSR_b_P1C68_Failed.Value, variation-point={short-label=vpOUT_VeESSR_b_P1C68_Failed_Value, sw-syscond=1}
              OUT_VeESSR_b_P1C64_Passed_Value: accessed-variable=VeESSR_b_P1C64_Passed.Value, variation-point={short-label=vpOUT_VeESSR_b_P1C64_Passed_Value, sw-syscond=1}
              OUT_VeESSR_b_P1C65_Passed_Value: accessed-variable=VeESSR_b_P1C65_Passed.Value, variation-point={short-label=vpOUT_VeESSR_b_P1C65_Passed_Value, sw-syscond=1}
              OUT_VeESSR_b_P1C68_Passed_Value: accessed-variable=VeESSR_b_P1C68_Passed.Value, variation-point={short-label=vpOUT_VeESSR_b_P1C68_Passed_Value, sw-syscond=1}
              OUT_VeESSR_e_HybEngSysActv_Value: accessed-variable=VeESSR_e_HybEngSysActv.Value, variation-point={short-label=vpOUT_VeESSR_e_HybEngSysActv_Value, sw-syscond=1}
              OUT_VeESSR_e_EngStartStopSt_Value: accessed-variable=VeESSR_e_EngStartStopSt.Value, variation-point={short-label=vpOUT_VeESSR_e_EngStartStopSt_Value, sw-syscond=1}
              OUT_VeESSR_e_TransFldPmpCmd_Value: accessed-variable=VeESSR_e_TransFldPmpCmd.Value, variation-point={short-label=vpOUT_VeESSR_e_TransFldPmpCmd_Value, sw-syscond=1}
              OUT_VeESSR_scl_SpdCtlGainMod_Value: accessed-variable=VeESSR_scl_SpdCtlGainMod.Value, variation-point={short-label=vpOUT_VeESSR_scl_SpdCtlGainMod_Value, sw-syscond=1}
              OUT_VeESSR_e_EngTrqRespType_Value: accessed-variable=VeESSR_e_EngTrqRespType.Value, variation-point={short-label=vpOUT_VeESSR_e_EngTrqRespType_Value, sw-syscond=1}
              OUT_VeESSR_M_EngTrqReqImmed_Value: accessed-variable=VeESSR_M_EngTrqReqImmed.Value, variation-point={short-label=vpOUT_VeESSR_M_EngTrqReqImmed_Value, sw-syscond=1}
              OUT_VeESSR_M_EngTrqReqPrdtd_Value: accessed-variable=VeESSR_M_EngTrqReqPrdtd.Value, variation-point={short-label=vpOUT_VeESSR_M_EngTrqReqPrdtd_Value, sw-syscond=1}
              OUT_VeESSR_b_EngDFCOOffHoldReq_Value: accessed-variable=VeESSR_b_EngDFCOOffHoldReq.Value, variation-point={short-label=vpOUT_VeESSR_b_EngDFCOOffHoldReq_Value, sw-syscond=1}
              OUT_VeESSR_b_EngStartAbort_Value: accessed-variable=VeESSR_b_EngStartAbort.Value, variation-point={short-label=vpOUT_VeESSR_b_EngStartAbort_Value, sw-syscond=1}
              OUT_VeESSR_b_AStrtPBatBoostReq_Value: accessed-variable=VeESSR_b_AStrtPBatBoostReq.Value, variation-point={short-label=vpOUT_VeESSR_b_AStrtPBatBoostReq_Value, sw-syscond=1}
              OUT_VeESSR_b_EngStrtStpActive_Value: accessed-variable=VeESSR_b_EngStrtStpActive.Value, variation-point={short-label=vpOUT_VeESSR_b_EngStrtStpActive_Value, sw-syscond=1}
              OUT_VeESSR_b_DisableNc1DotLim_Value: accessed-variable=VeESSR_b_DisableNc1DotLim.Value, variation-point={short-label=vpOUT_VeESSR_b_DisableNc1DotLim_Value, sw-syscond=1}
              OUT_VeESSR_e_EngStrtType_Value: accessed-variable=VeESSR_e_EngStrtType.Value, variation-point={short-label=vpOUT_VeESSR_e_EngStrtType_Value, sw-syscond=1}
              OUT_VeESSR_b_CltchStckOn_Value: accessed-variable=VeESSR_b_CltchStckOn.Value, variation-point={short-label=vpOUT_VeESSR_b_CltchStckOn_Value, sw-syscond=1}
              OUT_VeESSR_b_DsblNiClsdLoopCntrl_Value: accessed-variable=VeESSR_b_DsblNiClsdLoopCntrl.Value, variation-point={short-label=vpOUT_VeESSR_b_DsblNiClsdLoopCntrl_Value, sw-syscond=1}
              OUT_VeESSR_e_EngCntrlMode_Value: accessed-variable=VeESSR_e_EngCntrlMode.Value, variation-point={short-label=vpOUT_VeESSR_e_EngCntrlMode_Value, sw-syscond=1}
              OUT_VeESSR_b_AStrtFailed_Value: accessed-variable=VeESSR_b_AStrtFailed.Value, variation-point={short-label=vpOUT_VeESSR_b_AStrtFailed_Value, sw-syscond=1}
              OUT_VeESSR_b_HCP_StopStart_Fault_Value: accessed-variable=VeESSR_b_HCP_StopStart_Fault.Value, variation-point={short-label=vpOUT_VeESSR_b_HCP_StopStart_Fault_Value, sw-syscond=1}
              OUT_VeESSR_scl_AEMDMtrAGain_Value: accessed-variable=VeESSR_scl_AEMDMtrAGain.Value, variation-point={short-label=vpOUT_VeESSR_scl_AEMDMtrAGain_Value, sw-syscond=1}
              OUT_VeESSR_scl_AEMDMtrBGain_Value: accessed-variable=VeESSR_scl_AEMDMtrBGain.Value, variation-point={short-label=vpOUT_VeESSR_scl_AEMDMtrBGain_Value, sw-syscond=1}
              OUT_VeESSR_b_EngProdTrq_TCM_Value: accessed-variable=VeESSR_b_EngProdTrq_TCM.Value, variation-point={short-label=vpOUT_VeESSR_b_EngProdTrq_TCM_Value, sw-syscond=1}
              OUT_VeESSR_e_EngState_eTPUTgtSyncSt_Value: accessed-variable=VeESSR_e_EngState_eTPUTgtSyncSt.Value, variation-point={short-label=vpOUT_VeESSR_e_EngState_eTPUTgtSyncSt_Value, sw-syscond=1}
              OUT_VeESSR_e_TCM_StartStopType_Value: accessed-variable=VeESSR_e_TCM_StartStopType.Value, variation-point={short-label=vpOUT_VeESSR_e_TCM_StartStopType_Value, sw-syscond=1}
              OUT_VeESSR_e_EngStrtStpMd_Value: accessed-variable=VeESSR_e_EngStrtStpMd.Value, variation-point={short-label=vpOUT_VeESSR_e_EngStrtStpMd_Value, sw-syscond=1}
              OUT_VeESSR_M_MtrA_MaxTorq_Value: accessed-variable=VeESSR_M_MtrA_MaxTorq.Value, variation-point={short-label=vpOUT_VeESSR_M_MtrA_MaxTorq_Value, sw-syscond=1}
              OUT_VeESSR_M_MtrA_MinTorq_Value: accessed-variable=VeESSR_M_MtrA_MinTorq.Value, variation-point={short-label=vpOUT_VeESSR_M_MtrA_MinTorq_Value, sw-syscond=1}
              OUT_VeESSR_M_EngStrtTorq_Value: accessed-variable=VeESSR_M_EngStrtTorq.Value, variation-point={short-label=vpOUT_VeESSR_M_EngStrtTorq_Value, sw-syscond=1}
              OUT_VeESSR_n_NbTgt_Value: accessed-variable=VeESSR_n_NbTgt.Value, variation-point={short-label=vpOUT_VeESSR_n_NbTgt_Value, sw-syscond=1}
              OUT_VeESSR_b_BumpStrtsAllwd_Value: accessed-variable=VeESSR_b_BumpStrtsAllwd.Value, variation-point={short-label=vpOUT_VeESSR_b_BumpStrtsAllwd_Value, sw-syscond=1}
              OUT_VeESSR_g_StrtStpFailPhase_Value: accessed-variable=VeESSR_g_StrtStpFailPhase.Value, variation-point={short-label=vpOUT_VeESSR_g_StrtStpFailPhase_Value, sw-syscond=1}
              OUT_VeESSR_b_AStrtReattmptAllowed_Value: accessed-variable=VeESSR_b_AStrtReattmptAllowed.Value, variation-point={short-label=vpOUT_VeESSR_b_AStrtReattmptAllowed_Value, sw-syscond=1}
              OUT_VeESSR_n_StrtTypAStrtSpinUpExtSpd_Value: accessed-variable=VeESSR_n_StrtTypAStrtSpinUpExtSpd.Value, variation-point={short-label=vpOUT_VeESSR_n_StrtTypAStrtSpinUpExtSpd_Value, sw-syscond=1}
              OUT_VeESSR_i_CalLoader_Value: accessed-variable=VeESSR_i_CalLoader.Value, variation-point={short-label=vpOUT_VeESSR_i_CalLoader_Value, sw-syscond=1}
              OUT_VeESSR_b_TCMOpenDisconnctCltch_Value: accessed-variable=VeESSR_b_TCMOpenDisconnctCltch.Value, variation-point={short-label=vpOUT_VeESSR_b_TCMOpenDisconnctCltch_Value, sw-syscond=1}
              OUT_VeESSR_b_StrtStopFail_Value: accessed-variable=VeESSR_b_StrtStopFail.Value, variation-point={short-label=vpOUT_VeESSR_b_StrtStopFail_Value, sw-syscond=1}
              OUT_VeESSR_e_TCM_TransitionStatus_Value: accessed-variable=VeESSR_e_TCM_TransitionStatus.Value, variation-point={short-label=vpOUT_VeESSR_e_TCM_TransitionStatus_Value, sw-syscond=1}
              OUT_VeESSR_b_BackUpStartEng_Value: accessed-variable=VeESSR_b_BackUpStartEng.Value, variation-point={short-label=vpOUT_VeESSR_b_BackUpStartEng_Value, sw-syscond=1}
              OUT_VeESSR_M_MtrB_MaxTorq_Value: accessed-variable=VeESSR_M_MtrB_MaxTorq.Value, variation-point={short-label=vpOUT_VeESSR_M_MtrB_MaxTorq_Value, sw-syscond=1}
              OUT_VeESSR_M_MtrB_MinTorq_Value: accessed-variable=VeESSR_M_MtrB_MinTorq.Value, variation-point={short-label=vpOUT_VeESSR_M_MtrB_MinTorq_Value, sw-syscond=1}
              OUT_VeESSR_b_DsblNc1ClsdLoopCntrl_Value: accessed-variable=VeESSR_b_DsblNc1ClsdLoopCntrl.Value, variation-point={short-label=vpOUT_VeESSR_b_DsblNc1ClsdLoopCntrl_Value, sw-syscond=1}
              OUT_VeESSR_M_Clch5_TorqCmd_Value: accessed-variable=VeESSR_M_Clch5_TorqCmd.Value, variation-point={short-label=vpOUT_VeESSR_M_Clch5_TorqCmd_Value, sw-syscond=1}
              OUT_VeESSR_M_MtrC_MaxTorq_Value: accessed-variable=VeESSR_M_MtrC_MaxTorq.Value, variation-point={short-label=vpOUT_VeESSR_M_MtrC_MaxTorq_Value, sw-syscond=1}
              OUT_VeESSR_M_MtrC_MinTorq_Value: accessed-variable=VeESSR_M_MtrC_MinTorq.Value, variation-point={short-label=vpOUT_VeESSR_M_MtrC_MinTorq_Value, sw-syscond=1}
              OUT_VeESSR_b_NbTgtReq_Value: accessed-variable=VeESSR_b_NbTgtReq.Value, variation-point={short-label=vpOUT_VeESSR_b_NbTgtReq_Value, sw-syscond=1}
              OUT_VeESSR_b_EngStallReattmpAllwd_Value: accessed-variable=VeESSR_b_EngStallReattmpAllwd.Value, variation-point={short-label=vpOUT_VeESSR_b_EngStallReattmpAllwd_Value, sw-syscond=1}
              OUT_VeESSR_b_InhibitShiftToMode_Value: accessed-variable=VeESSR_b_InhibitShiftToMode.Value, variation-point={short-label=vpOUT_VeESSR_b_InhibitShiftToMode_Value, sw-syscond=1}
              OUT_VeESSR_b_BSGStrtFailed_Value: accessed-variable=VeESSR_b_BSGStrtFailed.Value, variation-point={short-label=vpOUT_VeESSR_b_BSGStrtFailed_Value, sw-syscond=1}
              OUT_VeESSR_b_BkupStrtsAllwd_Value: accessed-variable=VeESSR_b_BkupStrtsAllwd.Value, variation-point={short-label=vpOUT_VeESSR_b_BkupStrtsAllwd_Value, sw-syscond=1}
              OUT_VeESSR_Cnt_CSSpinupAttmptCntr_Value: accessed-variable=VeESSR_Cnt_CSSpinupAttmptCntr.Value, variation-point={short-label=vpOUT_VeESSR_Cnt_CSSpinupAttmptCntr_Value, sw-syscond=1}
              OUT_VeESSR_Cnt_EMSpinupAttmptCntr_Value: accessed-variable=VeESSR_Cnt_EMSpinupAttmptCntr.Value, variation-point={short-label=vpOUT_VeESSR_Cnt_EMSpinupAttmptCntr_Value, sw-syscond=1}
              OUT_VeESSR_e_EngStrtProfType_Value: accessed-variable=VeESSR_e_EngStrtProfType.Value, variation-point={short-label=vpOUT_VeESSR_e_EngStrtProfType_Value, sw-syscond=1}
              OUT_VeESSR_n_OptInputSpd_Value: accessed-variable=VeESSR_n_OptInputSpd.Value, variation-point={short-label=vpOUT_VeESSR_n_OptInputSpd_Value, sw-syscond=1}
              OUT_VeESSR_n_TgtIdleSpd_Value: accessed-variable=VeESSR_n_TgtIdleSpd.Value, variation-point={short-label=vpOUT_VeESSR_n_TgtIdleSpd_Value, sw-syscond=1}
              OUT_VeESSR_b_OptimdEngOnOffCmd_Value: accessed-variable=VeESSR_b_OptimdEngOnOffCmd.Value, variation-point={short-label=vpOUT_VeESSR_b_OptimdEngOnOffCmd_Value, sw-syscond=1}
              OUT_VeESSR_b_HCPFuelDisable_Value: accessed-variable=VeESSR_b_HCPFuelDisable.Value, variation-point={short-label=vpOUT_VeESSR_b_HCPFuelDisable_Value, sw-syscond=1}
              OUT_VeESSR_b_Hyb_ProducingTorque_Value: accessed-variable=VeESSR_b_Hyb_ProducingTorque.Value, variation-point={short-label=vpOUT_VeESSR_b_Hyb_ProducingTorque_Value, sw-syscond=1}
              OUT_VeESSR_n_InputSpeedProfile_Value: accessed-variable=VeESSR_n_InputSpeedProfile.Value, variation-point={short-label=vpOUT_VeESSR_n_InputSpeedProfile_Value, sw-syscond=1}
              OUT_VeESSR_e_OptimdEngStrtStpType_Value: accessed-variable=VeESSR_e_OptimdEngStrtStpType.Value, variation-point={short-label=vpOUT_VeESSR_e_OptimdEngStrtStpType_Value, sw-syscond=1}
              OUT_VeESSR_e_OptimdStrtReqdActr_Value: accessed-variable=VeESSR_e_OptimdStrtReqdActr.Value, variation-point={short-label=vpOUT_VeESSR_e_OptimdStrtReqdActr_Value, sw-syscond=1}
              OUT_VeESSR_b_EngOffAllwdECM_Value: accessed-variable=VeESSR_b_EngOffAllwdECM.Value, variation-point={short-label=vpOUT_VeESSR_b_EngOffAllwdECM_Value, sw-syscond=1}
              OUT_VeESSR_r_MaxSparkAuthority_Value: accessed-variable=VeESSR_r_MaxSparkAuthority.Value, variation-point={short-label=vpOUT_VeESSR_r_MaxSparkAuthority_Value, sw-syscond=1}
              OUT_VeESSR_dn_InputAcceltnProf_Value: accessed-variable=VeESSR_dn_InputAcceltnProf.Value, variation-point={short-label=vpOUT_VeESSR_dn_InputAcceltnProf_Value, sw-syscond=1}
              OUT_VeESSR_M_EngineLosses_Value: accessed-variable=VeESSR_M_EngineLosses.Value, variation-point={short-label=vpOUT_VeESSR_M_EngineLosses_Value, sw-syscond=1}
              OUT_VeESSR_n_NiPred_Value: accessed-variable=VeESSR_n_NiPred.Value, variation-point={short-label=vpOUT_VeESSR_n_NiPred_Value, sw-syscond=1}
              OUT_VeESSR_b_InputTorqOverride_Value: accessed-variable=VeESSR_b_InputTorqOverride.Value, variation-point={short-label=vpOUT_VeESSR_b_InputTorqOverride_Value, sw-syscond=1}
              OUT_VeESSR_M_EngTorqEst_Value: accessed-variable=VeESSR_M_EngTorqEst.Value, variation-point={short-label=vpOUT_VeESSR_M_EngTorqEst_Value, sw-syscond=1}
              OUT_VeESSR_b_DisableMtrA_Value: accessed-variable=VeESSR_b_DisableMtrA.Value, variation-point={short-label=vpOUT_VeESSR_b_DisableMtrA_Value, sw-syscond=1}
              OUT_VeESSR_M_BCTiMargin_Value: accessed-variable=VeESSR_M_BCTiMargin.Value, variation-point={short-label=vpOUT_VeESSR_M_BCTiMargin_Value, sw-syscond=1}
              OUT_VeESSR_g_StrtStpFailRsn_Value: accessed-variable=VeESSR_g_StrtStpFailRsn.Value, variation-point={short-label=vpOUT_VeESSR_g_StrtStpFailRsn_Value, sw-syscond=1}
        ESSR_PwrOff
          data-send-points:
            7 x access:
              OUT_NeESSR_M_SpinDwnAddtlOffset_NeESSR_M_SpinDwnAddtlOffset: accessed-variable=NeESSR_M_SpinDwnAddtlOffset.NeESSR_M_SpinDwnAddtlOffset
              OUT_NeESSR_M_SpinUpAddtlOffset_NeESSR_M_SpinUpAddtlOffset: accessed-variable=NeESSR_M_SpinUpAddtlOffset.NeESSR_M_SpinUpAddtlOffset
              OUT_NeESSR_g_StrtStpFailRsn_NeESSR_g_StrtStpFailRsn: accessed-variable=NeESSR_g_StrtStpFailRsn.NeESSR_g_StrtStpFailRsn
              OUT_NeESSR_g_StrtStpFailRsn2_NeESSR_g_StrtStpFailRsn2: accessed-variable=NeESSR_g_StrtStpFailRsn2.NeESSR_g_StrtStpFailRsn2
              OUT_NeESSR_Cnt_AdptInitValue_NeESSR_Cnt_AdptInitValue: accessed-variable=NeESSR_Cnt_AdptInitValue.NeESSR_Cnt_AdptInitValue
              OUT_NeESSR_k_EngStpProfAngAdpt_NeESSR_k_EngStpProfAngAdpt: accessed-variable=NeESSR_k_EngStpProfAngAdpt.NeESSR_k_EngStpProfAngAdpt
              OUT_NeESSR_k_EngStpProfNiDotGainAdapt_NeESSR_k_EngStpProfNiDotGainAdapt: accessed-variable=NeESSR_k_EngStpProfNiDotGainAdapt.NeESSR_k_EngStpProfNiDotGainAdapt
      8 x variation point proxy, all with category=CONDITION:
        Variant_ESSR_12vBSG: condition-access=0
        Variant_ESSR_BlueNexus: condition-access=0
        Variant_ESSR_Func: condition-access=0
        Variant_ESSR_LQIR: condition-access=0
        Variant_ESSR_Limphome: condition-access=0
        Variant_ESSR_NF: condition-access=1
        Variant_ESSR_P1P2Func: condition-access=0
        Variant_ESSR_P1P2p5Func: condition-access=0
